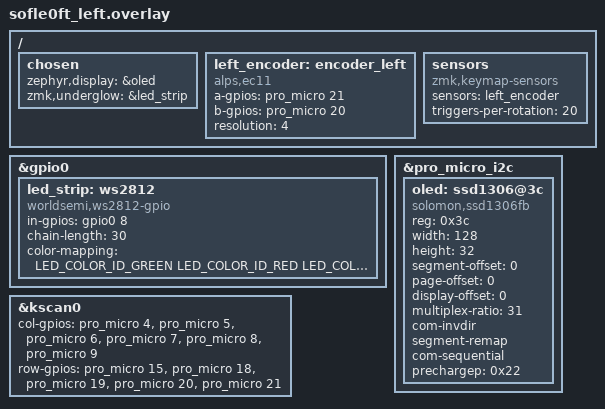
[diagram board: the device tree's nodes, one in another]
// Sofle v2 - Left half (central, nice!nano v2)
#include <dt-bindings/led/led.h>
#include "sofle0ft.dtsi"

// CHOSEN nodes
/ {
    chosen {
        zephyr,display = &oled;
        zmk,underglow = &led_strip;
    };

    left_encoder: encoder_left {
        compatible = "alps,ec11";
        a-gpios = <&pro_micro 21 (GPIO_ACTIVE_HIGH | GPIO_PULL_UP)>;
        b-gpios = <&pro_micro 20 (GPIO_ACTIVE_HIGH | GPIO_PULL_UP)>;
        resolution = <4>;
        status = "okay";
    };

    sensors: sensors {
        compatible = "zmk,keymap-sensors";
        sensors = <&left_encoder>;
        triggers-per-rotation = <20>;
    };
};

// WS2812 via GPIO - data pin P0.08 (pro_micro pin 6 on nice!nano v2)
// Change gpio0 pin number to match your actual LED data wire
&gpio0 {
    status = "okay";

    led_strip: ws2812 {
        compatible = "worldsemi,ws2812-gpio";
        status = "okay";
        in-gpios = <&gpio0 8 GPIO_ACTIVE_HIGH>;
        chain-length = <30>;
        color-mapping = <LED_COLOR_ID_GREEN
                         LED_COLOR_ID_RED
                         LED_COLOR_ID_BLUE>;
    };
};

// OLED SSD1306 128x32 via I2C
&pro_micro_i2c {
    status = "okay";

    oled: ssd1306@3c {
        compatible = "solomon,ssd1306fb";
        reg = <0x3c>;
        width = <128>;
        height = <32>;
        segment-offset = <0>;
        page-offset = <0>;
        display-offset = <0>;
        multiplex-ratio = <31>;
        com-invdir;
        segment-remap;
        com-sequential;
        prechargep = <0x22>;
    };
};

// Key matrix - left 5x6
&kscan0 {
    col-gpios
        = <&pro_micro 4  GPIO_ACTIVE_HIGH>
        , <&pro_micro 5  GPIO_ACTIVE_HIGH>
        , <&pro_micro 6  GPIO_ACTIVE_HIGH>
        , <&pro_micro 7  GPIO_ACTIVE_HIGH>
        , <&pro_micro 8  GPIO_ACTIVE_HIGH>
        , <&pro_micro 9  GPIO_ACTIVE_HIGH>
        ;
    row-gpios
        = <&pro_micro 15 (GPIO_ACTIVE_HIGH | GPIO_PULL_DOWN)>
        , <&pro_micro 18 (GPIO_ACTIVE_HIGH | GPIO_PULL_DOWN)>
        , <&pro_micro 19 (GPIO_ACTIVE_HIGH | GPIO_PULL_DOWN)>
        , <&pro_micro 20 (GPIO_ACTIVE_HIGH | GPIO_PULL_DOWN)>
        , <&pro_micro 21 (GPIO_ACTIVE_HIGH | GPIO_PULL_DOWN)>
        ;
};
